# STM32L4Q5xx register map
File version: 1.0
Registers are 32-bit, access not given, reset 0x0 unless marked. A register's access mark holds for its fields unless they carry their own. Offsets are from the block's base; [hi:lo] are bit positions; {n}, {i} and the like mark numbered series; 'fields as' and 'values as' point back to an identical list.

## ADC12_COMMON
Base 0x50040300
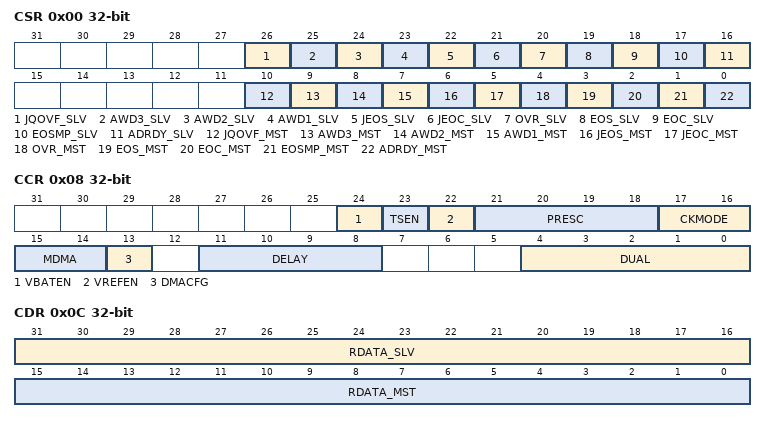
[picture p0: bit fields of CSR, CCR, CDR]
0x00 CSR
  [26] JQOVF_SLV, [25] AWD3_SLV, [24] AWD2_SLV, [23] AWD1_SLV, [22] JEOS_SLV, [21] JEOC_SLV, [20] OVR_SLV, [19] EOS_SLV, [18] EOC_SLV, [17] EOSMP_SLV, [16] ADRDY_SLV, [10] JQOVF_MST, [9] AWD3_MST, [8] AWD2_MST, [7] AWD1_MST, [6] JEOS_MST, [5] JEOC_MST, [4] OVR_MST, [3] EOS_MST, [2] EOC_MST, [1] EOSMP_MST, [0] ADRDY_MST
0x08 CCR
  [24] VBATEN, [23] TSEN, [22] VREFEN, [21:18] PRESC, [17:16] CKMODE, [15:14] MDMA, [13] DMACFG, [11:8] DELAY, [4:0] DUAL
0x0C CDR
  [31:16] RDATA_SLV, [15:0] RDATA_MST

## DCMI
Base 0x50050000
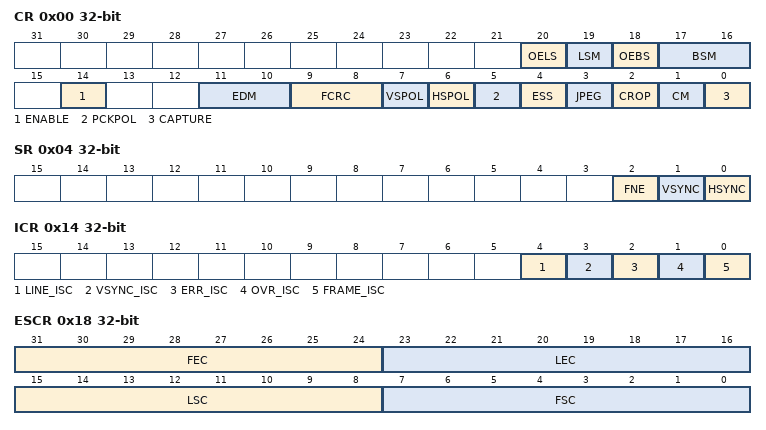
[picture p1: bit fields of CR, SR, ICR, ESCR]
0x00 CR
  [20] OELS, [19] LSM, [18] OEBS, [17:16] BSM, [14] ENABLE, [11:10] EDM, [9:8] FCRC, [7] VSPOL, [6] HSPOL, [5] PCKPOL, [4] ESS, [3] JPEG, [2] CROP, [1] CM, [0] CAPTURE
0x04 SR
  [2] FNE, [1] VSYNC, [0] HSYNC
0x08 RISR
0x0C IER
  [4] LINE_IE, [3] VSYNC_IE, [2] ERR_IE, [1] OVR_IE, [4:0] INT_IE
0x10 MISR
0x14 ICR
  [4] LINE_ISC, [3] VSYNC_ISC, [2] ERR_ISC, [1] OVR_ISC, [0] FRAME_ISC
0x18 ESCR
  [31:24] FEC, [23:16] LEC, [15:8] LSC, [7:0] FSC
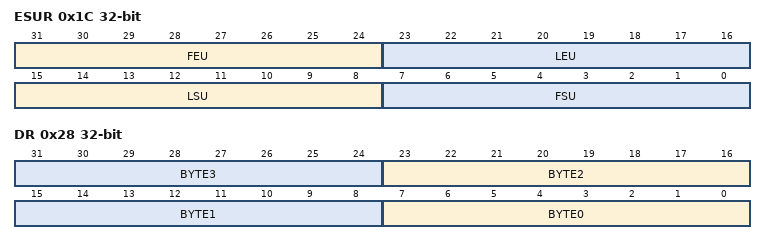
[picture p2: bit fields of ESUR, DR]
0x1C ESUR
  [31:24] FEU, [23:16] LEU, [15:8] LSU, [7:0] FSU
0x20 CWSTRTR
0x24 CWSIZER
0x28 DR
  [8n+7:8n] BYTE{n} (n=0..3)

## PSSI
Base 0x50050400
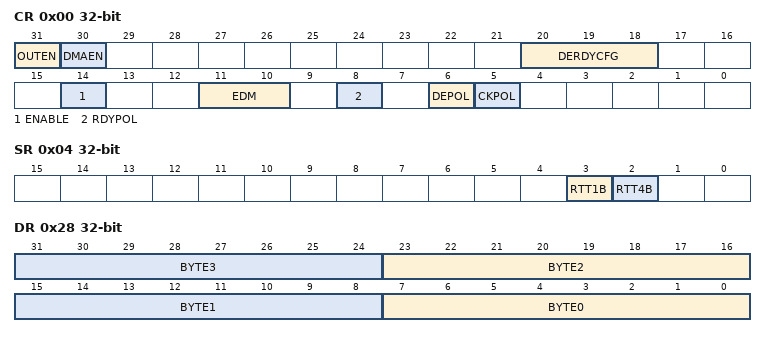
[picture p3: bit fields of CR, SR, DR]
0x00 CR
  [31] OUTEN, [30] DMAEN, [20:18] DERDYCFG, [14] ENABLE, [11:10] EDM, [8] RDYPOL, [6] DEPOL, [5] CKPOL
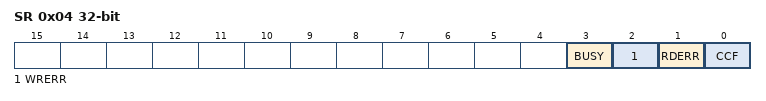
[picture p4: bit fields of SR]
0x04 SR
  [3] RTT1B, [2] RTT4B
0x08 RIS
  [1] OVR_RIS
0x0C IER
  [1] OVR_IE
0x10 MIS
  [1] OVR_MIS
0x14 ICR
  [1] OVR_ISC
0x28 DR
  [8n+7:8n] BYTE{n} (n=0..3)
0x3F0 HWCFGR
0x3F4 VERR
0x3F8 IPIDR
0x3FC SIDR

## AES
Base 0x50060000
0x00 CR
  [23:20] NPBLB, [18] KEYSIZE, [14:13] GCMPH, [12] DMAOUTEN, [11] DMAINEN, [10] ERRIE, [9] CCFIE, [8] ERRC, [7] CCFC, [16:5] CHMOD, [4:3] MODE, [2:1] DATATYPE, [0] EN
0x04 SR
  [3] BUSY, [2] WRERR, [1] RDERR, [0] CCF
0x08 DINR
0x0C DOUTR
{0x10+4i} KEYR{i} (i=0..3)
{0x20+4i} IVR{i} (i=0..3)
{0x20+4i} KEYR{i} (i=4..7)
{0x40+4i} SUSP{i}R (i=0..7)

## HASH
Base 0x50060400
0x00 CR
  [16] LKEY, [13] MDMAT, [12] DINNE, [11:8] NBW, [18:7] ALGO, [6] MODE, [5:4] DATATYPE, [3] DMAE, [2] INIT
0x04 DIN
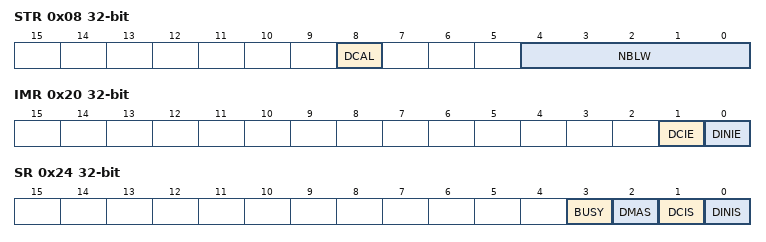
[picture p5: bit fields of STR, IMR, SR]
0x08 STR
  [8] DCAL, [4:0] NBLW
0x0C HR.0
0x10 HR.1
0x14 HR.2
0x18 HR.3
0x1C HR.4
0x20 IMR
  [1] DCIE, [0] DINIE
0x24 SR
  [3] BUSY, [2] DMAS, [1] DCIS, [0] DINIS
0xF8 CSR.0
0xFC CSR.1
0x100 CSR.2
0x104 CSR.3
0x108 CSR.4
0x10C CSR.5
0x110 CSR.6
0x114 CSR.7
0x118 CSR.8
0x11C CSR.9
0x120 CSR.10
0x124 CSR.11
0x128 CSR.12
0x12C CSR.13
0x130 CSR.14
0x134 CSR.15
0x138 CSR.16
0x13C CSR.17
0x140 CSR.18
0x144 CSR.19
0x148 CSR.20
0x14C CSR.21
0x150 CSR.22
0x154 CSR.23
0x158 CSR.24
0x15C CSR.25
0x160 CSR.26
0x164 CSR.27
0x168 CSR.28
0x16C CSR.29
0x170 CSR.30
0x174 CSR.31
0x178 CSR.32
0x17C CSR.33
0x180 CSR.34
0x184 CSR.35
0x188 CSR.36
0x18C CSR.37
0x190 CSR.38
0x194 CSR.39
0x198 CSR.40
0x19C CSR.41
0x1A0 CSR.42
0x1A4 CSR.43
0x1A8 CSR.44
0x1AC CSR.45
0x1B0 CSR.46
0x1B4 CSR.47
0x1B8 CSR.48
0x1BC CSR.49
0x1C0 CSR.50
0x1C4 CSR.51
0x1C8 CSR.52
0x1CC CSR.53

## HASH_DIGEST
Base 0x50060710
0x00 HR.0
0x04 HR.1
0x08 HR.2
0x0C HR.3
0x10 HR.4
0x14 HR.5
0x18 HR.6
0x1C HR.7

## RNG
Base 0x50060800
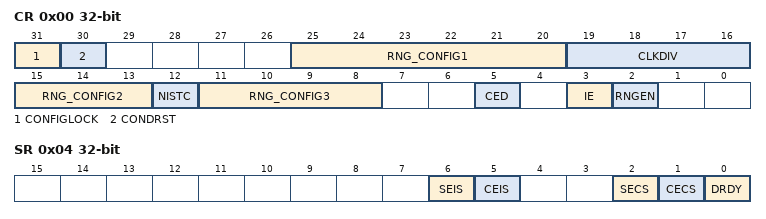
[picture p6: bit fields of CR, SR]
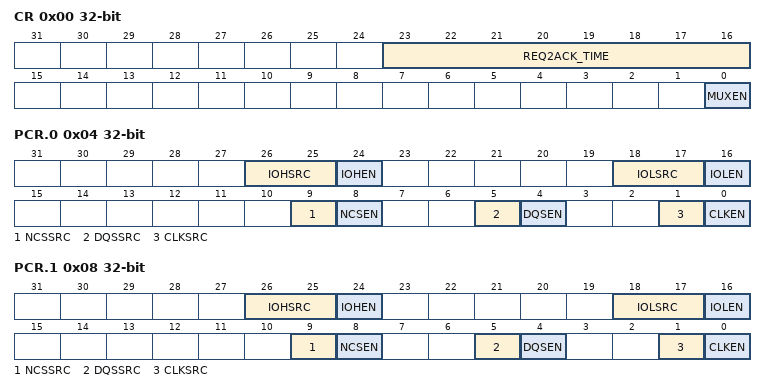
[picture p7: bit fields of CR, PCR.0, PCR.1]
0x00 CR
  [31] CONFIGLOCK, [30] CONDRST, [25:20] RNG_CONFIG1, [19:16] CLKDIV, [15:13] RNG_CONFIG2, [12] NISTC, [11:8] RNG_CONFIG3, [5] CED, [3] IE, [2] RNGEN
0x04 SR
  [6] SEIS, [5] CEIS, [2] SECS, [1] CECS, [0] DRDY
0x08 DR
0x10 HTCR

## OCTOSPIM
Base 0x50061C00
0x00 CR
  [23:16] REQ2ACK_TIME, [0] MUXEN
0x04 PCR.0
  [26:25] IOHSRC, [24] IOHEN, [18:17] IOLSRC, [16] IOLEN, [9] NCSSRC, [8] NCSEN, [5] DQSSRC, [4] DQSEN, [1] CLKSRC, [0] CLKEN
0x08 PCR.1
  fields as PCR.0

## SDMMC1
Base 0x50062400
Same registers: SDMMC2 0x50062800
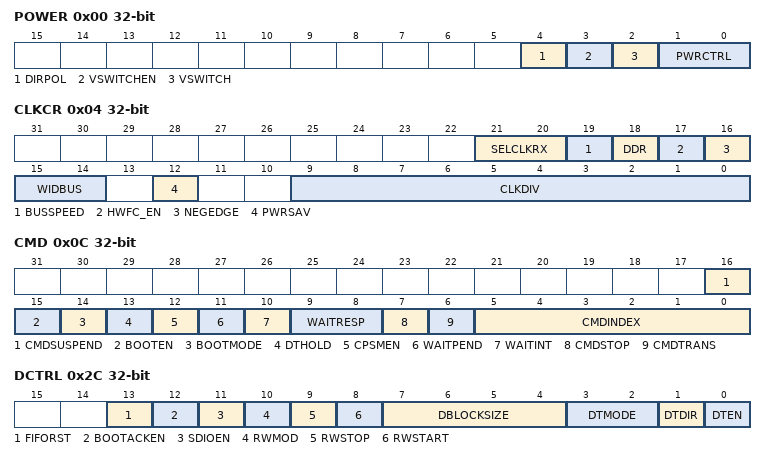
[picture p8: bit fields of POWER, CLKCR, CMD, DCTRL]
0x00 POWER
  [4] DIRPOL, [3] VSWITCHEN, [2] VSWITCH, [1:0] PWRCTRL
0x04 CLKCR
  [21:20] SELCLKRX, [19] BUSSPEED, [18] DDR, [17] HWFC_EN, [16] NEGEDGE, [15:14] WIDBUS, [12] PWRSAV, [9:0] CLKDIV
0x08 ARG
  [31:0] CMDARG
0x0C CMD
  [16] CMDSUSPEND, [15] BOOTEN, [14] BOOTMODE, [13] DTHOLD, [12] CPSMEN, [11] WAITPEND, [10] WAITINT, [9:8] WAITRESP, [7] CMDSTOP, [6] CMDTRANS, [5:0] CMDINDEX
0x10 RESPCMD
  [5:0] RESPCMD
{0x10+4i} RESP{i} (i=1..4)
  [31:0] CARDSTATUS{i}
0x24 DTIMER
  [31:0] DATATIME
0x28 DLEN
  [24:0] DATALENGTH
0x2C DCTRL
  [13] FIFORST, [12] BOOTACKEN, [11] SDIOEN, [10] RWMOD, [9] RWSTOP, [8] RWSTART, [7:4] DBLOCKSIZE, [3:2] DTMODE, [1] DTDIR, [0] DTEN
0x30 DCOUNT
  [24:0] DATACOUNT
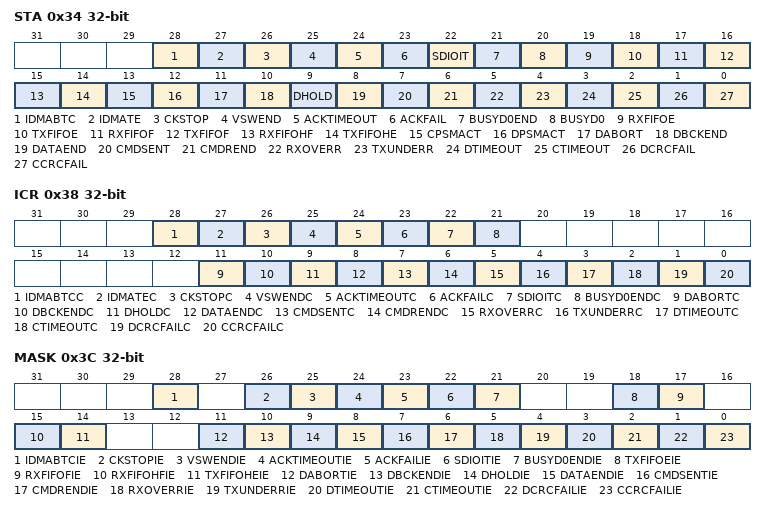
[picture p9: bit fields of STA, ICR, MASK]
0x34 STA
  [28] IDMABTC, [27] IDMATE, [26] CKSTOP, [25] VSWEND, [24] ACKTIMEOUT, [23] ACKFAIL, [22] SDIOIT, [21] BUSYD0END, [20] BUSYD0, [19] RXFIFOE, [18] TXFIFOE, [17] RXFIFOF, [16] TXFIFOF, [15] RXFIFOHF, [14] TXFIFOHE, [13] CPSMACT, [12] DPSMACT, [11] DABORT, [10] DBCKEND, [9] DHOLD, [8] DATAEND, [7] CMDSENT, [6] CMDREND, [5] RXOVERR, [4] TXUNDERR, [3] DTIMEOUT, [2] CTIMEOUT, [1] DCRCFAIL, [0] CCRCFAIL
0x38 ICR
  [28] IDMABTCC, [27] IDMATEC, [26] CKSTOPC, [25] VSWENDC, [24] ACKTIMEOUTC, [23] ACKFAILC, [22] SDIOITC, [21] BUSYD0ENDC, [11] DABORTC, [10] DBCKENDC, [9] DHOLDC, [8] DATAENDC, [7] CMDSENTC, [6] CMDRENDC, [5] RXOVERRC, [4] TXUNDERRC, [3] DTIMEOUTC, [2] CTIMEOUTC, [1] DCRCFAILC, [0] CCRCFAILC
0x3C MASK
  [28] IDMABTCIE, [26] CKSTOPIE, [25] VSWENDIE, [24] ACKTIMEOUTIE, [23] ACKFAILIE, [22] SDIOITIE, [21] BUSYD0ENDIE, [18] TXFIFOEIE, [17] RXFIFOFIE, [15] RXFIFOHFIE, [14] TXFIFOHEIE, [11] DABORTIE, [10] DBCKENDIE, [9] DHOLDIE, [8] DATAENDIE, [7] CMDSENTIE, [6] CMDRENDIE, [5] RXOVERRIE, [4] TXUNDERRIE, [3] DTIMEOUTIE, [2] CTIMEOUTIE, [1] DCRCFAILIE, [0] CCRCFAILIE
0x40 ACKTIME
0x50 IDMACTRL
0x54 IDMABSIZE
0x58 IDMABASE0
0x5C IDMABASE1
0x80 FIFO
  [31:0] FIFODATA

## FMC_Bank1_R
Base 0xA0000000
0x00 BTCR.0
0x04 BTCR.1
0x08 BTCR.2
0x0C BTCR.3
0x10 BTCR.4
0x14 BTCR.5
0x18 BTCR.6
0x1C BTCR.7
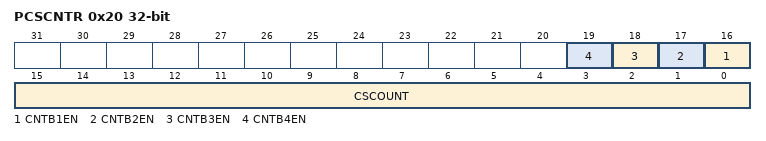
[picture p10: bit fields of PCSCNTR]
0x20 PCSCNTR
  [n+15] CNTB{n}EN (n=1..4), [15:0] CSCOUNT

## FMC_Bank3_R
Base 0xA0000080
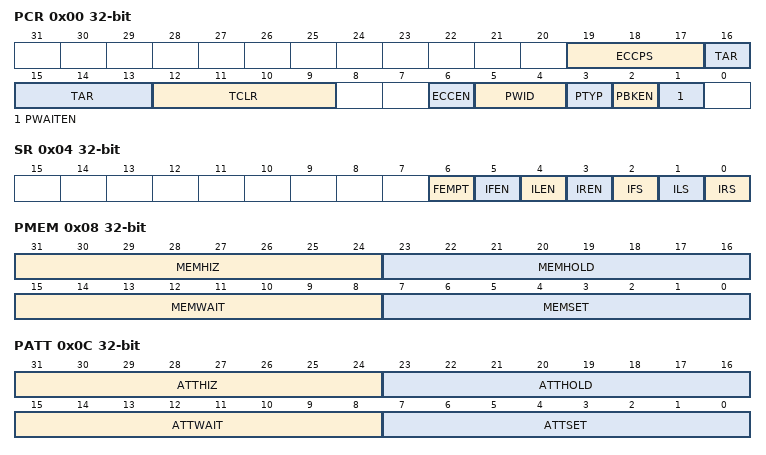
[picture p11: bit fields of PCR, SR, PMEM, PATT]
0x00 PCR
  [19:17] ECCPS, [16:13] TAR, [12:9] TCLR, [6] ECCEN, [5:4] PWID, [3] PTYP, [2] PBKEN, [1] PWAITEN
0x04 SR
  [6] FEMPT, [5] IFEN, [4] ILEN, [3] IREN, [2] IFS, [1] ILS, [0] IRS
0x08 PMEM
  [31:24] MEMHIZ, [23:16] MEMHOLD, [15:8] MEMWAIT, [7:0] MEMSET
0x0C PATT
  [31:24] ATTHIZ, [23:16] ATTHOLD, [15:8] ATTWAIT, [7:0] ATTSET
0x14 ECCR
  [31:0] ECC

## FMC_Bank1E_R
Base 0xA0000104
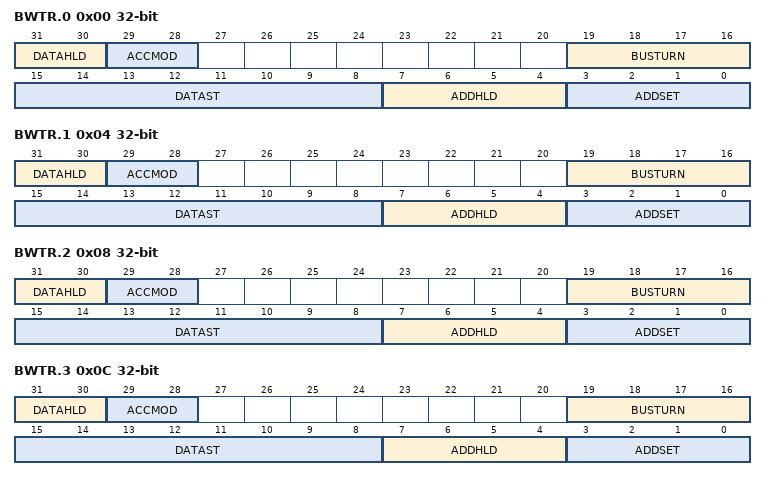
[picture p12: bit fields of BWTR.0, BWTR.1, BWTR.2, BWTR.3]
0x00 BWTR.0
  [31:30] DATAHLD, [29:28] ACCMOD, [19:16] BUSTURN, [15:8] DATAST, [7:4] ADDHLD, [3:0] ADDSET
0x04 BWTR.1
  fields as BWTR.0
0x08 BWTR.2
  fields as BWTR.0
0x0C BWTR.3
  fields as BWTR.0
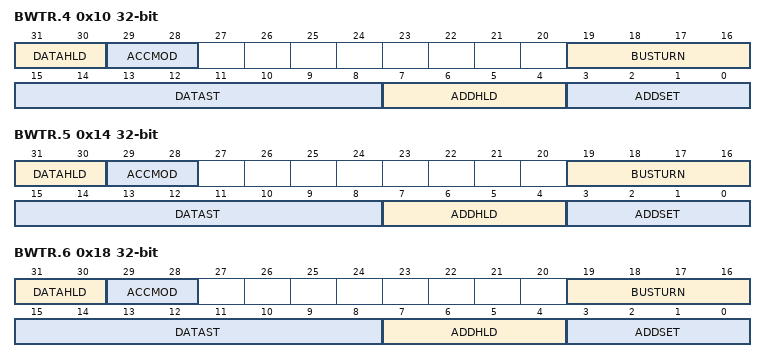
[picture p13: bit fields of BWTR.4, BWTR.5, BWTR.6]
0x10 BWTR.4
  fields as BWTR.0
0x14 BWTR.5
  fields as BWTR.0
0x18 BWTR.6
  fields as BWTR.0

## OCTOSPI1
Base 0xA0001000
Same registers: OCTOSPI2 0xA0001400
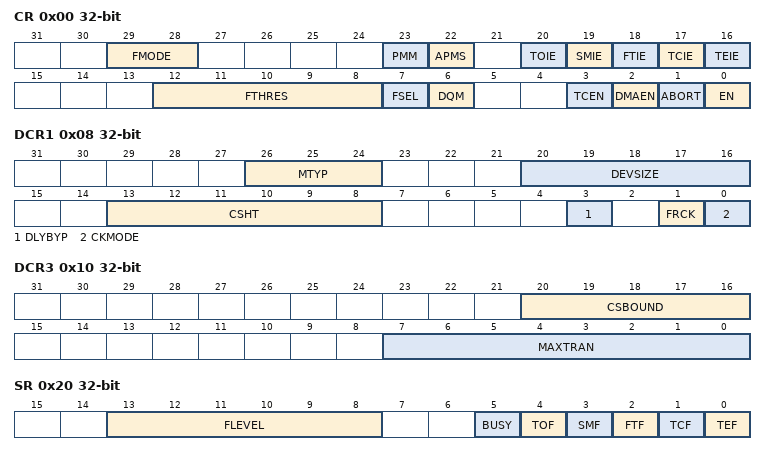
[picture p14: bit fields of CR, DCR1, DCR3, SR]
0x00 CR
  [29:28] FMODE, [23] PMM, [22] APMS, [20] TOIE, [19] SMIE, [18] FTIE, [17] TCIE, [16] TEIE, [12:8] FTHRES, [7] FSEL, [6] DQM, [3] TCEN, [2] DMAEN, [1] ABORT, [0] EN
0x08 DCR1
  [26:24] MTYP, [20:16] DEVSIZE, [13:8] CSHT, [3] DLYBYP, [1] FRCK, [0] CKMODE
0x0C DCR2
  [7:0] PRESCALER
0x10 DCR3
  [20:16] CSBOUND, [7:0] MAXTRAN
0x14 DCR4
  [31:0] REFRESH
0x20 SR
  [13:8] FLEVEL, [5] BUSY, [4] TOF, [3] SMF, [2] FTF, [1] TCF, [0] TEF
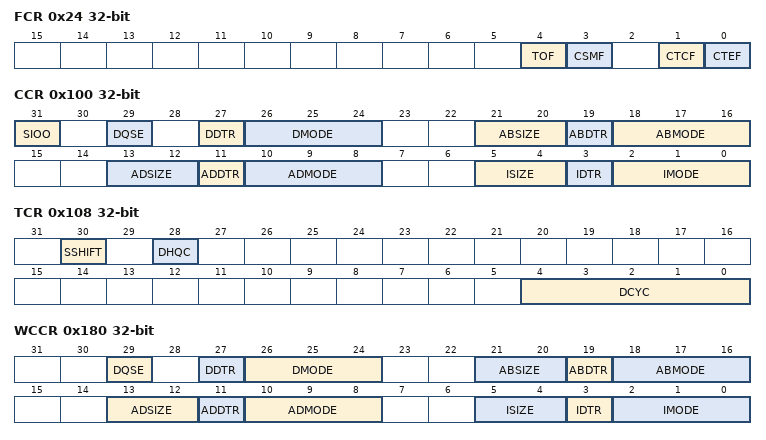
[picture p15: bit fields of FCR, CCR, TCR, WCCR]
0x24 FCR
  [4] TOF, [3] CSMF, [1] CTCF, [0] CTEF
0x40 DLR
  [31:0] DL
0x48 AR
  [31:0] ADDRESS
0x50 DR
  [31:0] DATA
0x80 PSMKR
  [31:0] MASK
0x88 PSMAR
  [31:0] MATCH
0x90 PIR
  [15:0] INTERVAL
0x100 CCR
  [31] SIOO, [29] DQSE, [27] DDTR, [26:24] DMODE, [21:20] ABSIZE, [19] ABDTR, [18:16] ABMODE, [13:12] ADSIZE, [11] ADDTR, [10:8] ADMODE, [5:4] ISIZE, [3] IDTR, [2:0] IMODE
0x108 TCR
  [30] SSHIFT, [28] DHQC, [4:0] DCYC
0x110 IR
  [31:0] INSTRUCTION
0x120 ABR
  [31:0] ALTERNATE
0x130 LPTR
  [15:0] TIMEOUT
0x180 WCCR
  [29] DQSE, [27] DDTR, [26:24] DMODE, [21:20] ABSIZE, [19] ABDTR, [18:16] ABMODE, [13:12] ADSIZE, [11] ADDTR, [10:8] ADMODE, [5:4] ISIZE, [3] IDTR, [2:0] IMODE
0x188 WTCR
  [4:0] DCYC
0x190 WIR
  [31:0] INSTRUCTION
0x1A0 WABR
  [31:0] ALTERNATE
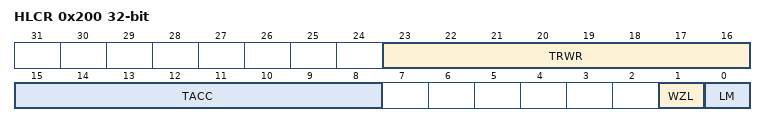
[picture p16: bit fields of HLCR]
0x200 HLCR
  [23:16] TRWR, [15:8] TACC, [1] WZL, [0] LM

## DBGMCU
Base 0xE0042000
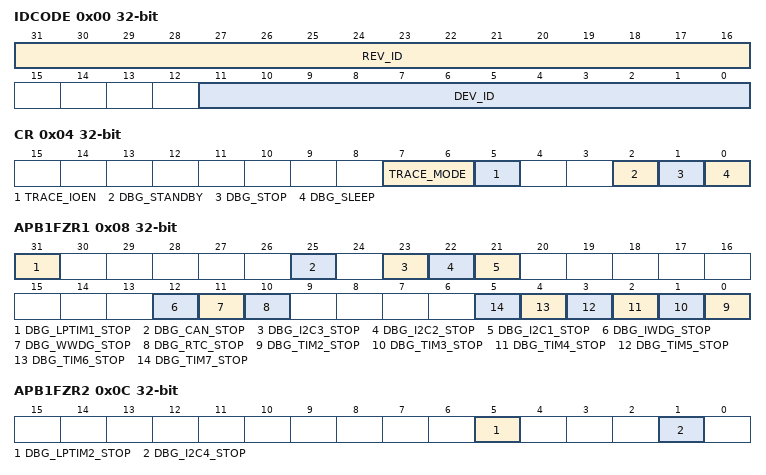
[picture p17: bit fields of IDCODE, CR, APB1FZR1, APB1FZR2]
0x00 IDCODE
  [31:16] REV_ID, [11:0] DEV_ID
0x04 CR
  [7:6] TRACE_MODE, [5] TRACE_IOEN, [2] DBG_STANDBY, [1] DBG_STOP, [0] DBG_SLEEP
0x08 APB1FZR1
  [31] DBG_LPTIM1_STOP, [25] DBG_CAN_STOP, [23] DBG_I2C3_STOP, [22] DBG_I2C2_STOP, [21] DBG_I2C1_STOP, [12] DBG_IWDG_STOP, [11] DBG_WWDG_STOP, [10] DBG_RTC_STOP, [n-2] DBG_TIM{n}_STOP (n=2..7)
0x0C APB1FZR2
  [5] DBG_LPTIM2_STOP, [1] DBG_I2C4_STOP
0x10 APB2FZ
  [18] DBG_TIM17_STOP, [17] DBG_TIM16_STOP, [16] DBG_TIM15_STOP, [13] DBG_TIM8_STOP, [11] DBG_TIM1_STOP
